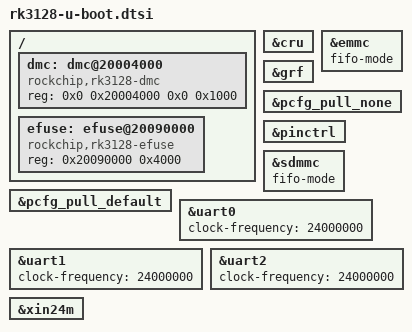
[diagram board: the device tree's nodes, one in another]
// SPDX-License-Identifier: GPL-2.0+

#include "rockchip-u-boot.dtsi"

/ {
	dmc: dmc@20004000 {
		compatible = "rockchip,rk3128-dmc", "syscon";
		reg = <0x0 0x20004000 0x0 0x1000>;
		bootph-all;
	};

	efuse: efuse@20090000 {
		compatible = "rockchip,rk3128-efuse";
		reg = <0x20090000 0x4000>;
	};
};

&cru {
	bootph-all;
};

&emmc {
	fifo-mode;
};

&grf {
	bootph-all;
};

&pcfg_pull_default {
	bootph-all;
};

&pcfg_pull_none {
	bootph-all;
};

&pinctrl {
	bootph-all;
};

&sdmmc {
	fifo-mode;
};

&uart0 {
	clock-frequency = <24000000>;
};

&uart1 {
	clock-frequency = <24000000>;
};

&uart2 {
	clock-frequency = <24000000>;
};

&xin24m {
	bootph-all;
};
